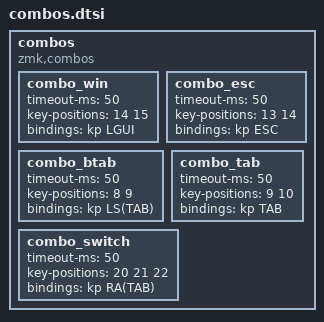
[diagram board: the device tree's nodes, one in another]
combos {
        compatible = "zmk,combos";
        combo_win {
            timeout-ms = <50>;
            key-positions = <14 15>;
            bindings = <&kp LGUI>;
        };

        combo_esc {
            timeout-ms = <50>;
            key-positions = <13 14>;
            bindings = <&kp ESC>;
        };

        combo_btab {
            timeout-ms = <50>;
            key-positions = <8 9>;
            bindings = <&kp LS(TAB)>;
        };

        combo_tab {
            timeout-ms = <50>;
            key-positions = <9 10>;
            bindings = <&kp TAB>;
        };

        combo_switch {
            timeout-ms = <50>;
            key-positions = <20 21 22>;
            bindings = <&kp RA(TAB)>;
        };
    };

    /*ZMK_COMBO(win,  &kp LGUI, 14 15, ALL, 25)
    ZMK_COMBO(esc,  &kp ESC, 13 14, ALL, 25)
    ZMK_COMBO(btab,  &kp LS(TAB), 8 9, ALL, 25)
    ZMK_COMBO(tab,  &kp TAB, 9 10, ALL, 25)
    ZMK_COMBO(switch,  &kp RA(TAB), 20 21 22, ALL, 25)*/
